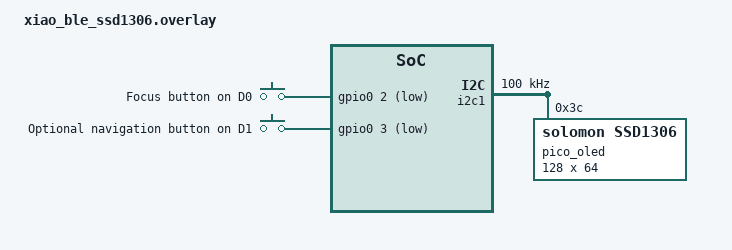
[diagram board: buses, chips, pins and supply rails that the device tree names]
/* XIAO nRF52840 Sense + four-pin 128x64 SSD1306 OLED, nRF Connect SDK 3.4.2.
 * VCC -> 3V3, GND -> GND, SDA -> D4/P0.04, SCL -> D5/P0.05.
 * i2c1 uses these header pins; i2c0 is the Sense board's internal IMU bus.
 */
#include <zephyr/dt-bindings/i2c/i2c.h>
#include <zephyr/dt-bindings/gpio/gpio.h>

/ {
    chosen {
        zephyr,display = &pico_oled;
    };

    buttons {
        compatible = "gpio-keys";
        pico_focus_button: focus_button {
            gpios = <&gpio0 2 (GPIO_PULL_UP | GPIO_ACTIVE_LOW)>;
            label = "Focus button on D0";
        };
        pico_nav_button: nav_button {
            gpios = <&gpio0 3 (GPIO_PULL_UP | GPIO_ACTIVE_LOW)>;
            label = "Optional navigation button on D1";
        };
    };

    aliases {
        pico-focus-button = &pico_focus_button;
        pico-nav-button = &pico_nav_button;
    };
};

&i2c1 {
    status = "okay";
    clock-frequency = <I2C_BITRATE_STANDARD>;

    pico_oled: ssd1306@3c {
        compatible = "solomon,ssd1306";
        reg = <0x3c>;
        width = <128>;
        height = <64>;
        segment-offset = <0>;
        page-offset = <0>;
        display-offset = <0>;
        multiplex-ratio = <63>;
        segment-remap;
        com-invdir;
        prechargep = <0x22>;
    };
};
